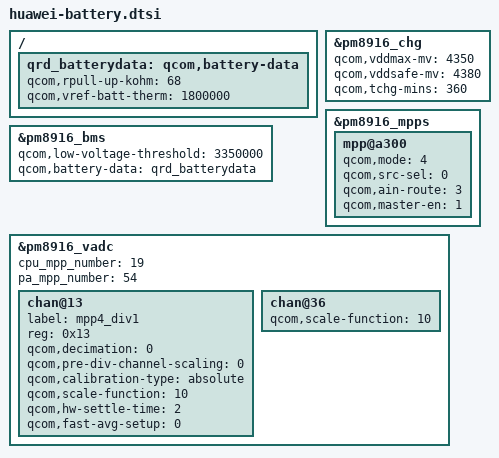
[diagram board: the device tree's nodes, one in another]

/ {
	qrd_batterydata: qcom,battery-data {
		qcom,rpull-up-kohm = <68>;
		qcom,vref-batt-therm = <1800000>;
	};
};

&pm8916_bms {
	status = "ok";
	qcom,low-voltage-threshold = <3350000>;
	qcom,battery-data = <&qrd_batterydata>;
};

&pm8916_chg {
	status = "okay";
	qcom,vddmax-mv = <4350>;
	qcom,vddsafe-mv = <4380>;
	qcom,tchg-mins = <360>;
};

&pm8916_mpps {
	mpp@a300 {
		qcom,mode = <4>; // QPNP_PIN_MODE_AIN
		qcom,src-sel = <0>; // QPNP_PIN_SEL_FUNC_CONSTANT
		qcom,ain-route = <3>; // QPNP_PIN_AIN_AMUX_CH8
		qcom,master-en = <1>; // Enable features
	};
};

&pm8916_vadc {
	cpu_mpp_number = <19>;
	pa_mpp_number = <54>;

	chan@13 {
		label = "mpp4_div1";
		reg = <0x13>;
		qcom,decimation = <0>; //512 sampling rate
		qcom,pre-div-channel-scaling = <0>; //1:1 scaling
		qcom,calibration-type = "absolute"; //Use 625mV & 1.25V reference voltage
		qcom,scale-function = <10>; //convert raw adc code to voltage
		qcom,hw-settle-time = <2>; //200us
		qcom,fast-avg-setup = <0>; //with only one average measurement
	};

	chan@36 {
		qcom,scale-function = <10>;
	};
};

